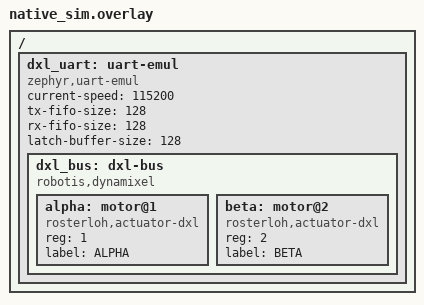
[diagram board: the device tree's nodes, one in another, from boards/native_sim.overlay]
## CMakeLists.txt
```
cmake_minimum_required(VERSION 3.20.0)
find_package(Zephyr REQUIRED HINTS $ENV{ZEPHYR_BASE})
project(actuator_dxl_tests)

set(DXL_TEST_SRC
    ${CMAKE_CURRENT_LIST_DIR}/../../dynamixel/src/fake_servo.c
    ${CMAKE_CURRENT_LIST_DIR}/../../dynamixel/src/fake_bus.c
)

target_sources(app PRIVATE
    src/main.c
    src/test_set_position.c
    src/test_group.c
    ${DXL_TEST_SRC}
)

zephyr_include_directories(../../dynamixel/src)
zephyr_include_directories(${ZEPHYR_DRIVERS_REPO_ROOT}/drivers/dynamixel)
```

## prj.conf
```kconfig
CONFIG_ZTEST=y
CONFIG_LOG=y
CONFIG_SERIAL=y
CONFIG_UART_INTERRUPT_DRIVEN=y
CONFIG_EMUL=y
CONFIG_UART_EMUL=y
CONFIG_ACTUATOR=y
CONFIG_ACTUATOR_DXL=y
CONFIG_DYNAMIXEL=y
CONFIG_FPU=y
# Higher tick resolution so that µs-level timeouts quantise accurately.
CONFIG_SYS_CLOCK_TICKS_PER_SEC=10000
```

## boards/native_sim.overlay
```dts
/*
 * Copyright (c) 2026 Richard Osterloh <richard.osterloh@gmail.com>
 *
 * SPDX-License-Identifier: Apache-2.0
 */

/ {
	dxl_uart: uart-emul {
		compatible = "zephyr,uart-emul";
		current-speed = <115200>;
		tx-fifo-size = <128>;
		rx-fifo-size = <128>;
		latch-buffer-size = <128>;
		status = "okay";

		dxl_bus: dxl-bus {
			compatible = "robotis,dynamixel";
			#address-cells = <1>;
			#size-cells = <0>;
			status = "okay";

			alpha: motor@1 {
				compatible = "rosterloh,actuator-dxl";
				reg = <1>;
				label = "ALPHA";
			};

			beta: motor@2 {
				compatible = "rosterloh,actuator-dxl";
				reg = <2>;
				label = "BETA";
			};
		};
	};
};
```

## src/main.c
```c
/*
 * Copyright (c) 2026 Richard Osterloh <richard.osterloh@gmail.com>
 * SPDX-License-Identifier: Apache-2.0
 */

#include <zephyr/ztest.h>

ZTEST_SUITE(dxl_actuator, NULL, NULL, NULL, NULL, NULL);
```

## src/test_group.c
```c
/*
 * Copyright (c) 2026 Richard Osterloh <richard.osterloh@gmail.com>
 * SPDX-License-Identifier: Apache-2.0
 */

#include <zephyr/ztest.h>
#include <zephyr/device.h>
#include <zephyr/actuator/actuator.h>
#include <zephyr/actuator/actuator_group.h>
#include <drivers/dynamixel.h>

#include "fake_bus.h"

#define DXL_BUS_NODE   DT_NODELABEL(dxl_bus)
#define DXL_UART_NODE  DT_PARENT(DXL_BUS_NODE)
#define DXL_IFACE_NAME DEVICE_DT_NAME(DXL_BUS_NODE)

#define FAKE_BUS_RXWAIT_TO_US 10000U

#define ALPHA DEVICE_DT_GET(DT_NODELABEL(alpha))
#define BETA  DEVICE_DT_GET(DT_NODELABEL(beta))

ACTUATOR_GROUP_DEFINE(arm, ALPHA, BETA);

static const struct device *uart_dev = DEVICE_DT_GET(DXL_UART_NODE);

static struct fake_bus bus;
static int iface;

static void grp_before_each(void *fixture)
{
	ARG_UNUSED(fixture);

	const uint8_t ids[] = {1, 2};
	struct dxl_iface_param p = {
		.rx_timeout = FAKE_BUS_RXWAIT_TO_US,
		.serial = {.baud = 115200, .parity = UART_CFG_PARITY_NONE},
	};

	fake_bus_init(&bus, ids, ARRAY_SIZE(ids));
	fake_bus_attach(&bus, uart_dev);

	iface = dxl_iface_get_by_name(DXL_IFACE_NAME);
	zassert_true(iface >= 0, "iface lookup failed: %d", iface);
	zassert_ok(dxl_init(iface, p), "dxl_init failed");
}

static void grp_after_each(void *fixture)
{
	ARG_UNUSED(fixture);
	dxl_disable(iface);
}

ZTEST_SUITE(dxl_actuator_grp, NULL, NULL, grp_before_each, grp_after_each, NULL);

ZTEST(dxl_actuator_grp, test_group_set_position_succeeds)
{
	struct fake_servo *s0 = fake_bus_get(&bus, 1);
	struct fake_servo *s1 = fake_bus_get(&bus, 2);

	zassert_not_null(s0, "servo 1 not found");
	zassert_not_null(s1, "servo 2 not found");

	zassert_ok(actuator_group_enable(&arm));

	s0->last_tx_len = 0;
	s0->last_instruction = 0;
	s1->last_tx_len = 0;
	s1->last_instruction = 0;

	const float goals[] = {1.0f, -1.0f};
	int err = actuator_group_set_position(&arm, goals);

	zassert_ok(err, "group_set_position rc=%d", err);

	/* SYNC_WRITE is fire-and-forget; yield for TX FIFO drain before asserting. */
	k_sleep(K_MSEC(2));

	/* SYNC_WRITE is broadcast: fake_bus captures the packet in all servos. */
	zassert_true(s0->last_tx_len > 0, "expected SYNC_WRITE bus traffic, got last_tx_len=%u",
		     s0->last_tx_len);
}
```

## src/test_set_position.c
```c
/*
 * Copyright (c) 2026 Richard Osterloh <richard.osterloh@gmail.com>
 * SPDX-License-Identifier: Apache-2.0
 */

#include <zephyr/ztest.h>
#include <zephyr/device.h>
#include <zephyr/actuator/actuator.h>
#include <drivers/dynamixel.h>

#include "fake_bus.h"

#define DXL_BUS_NODE   DT_NODELABEL(dxl_bus)
#define DXL_UART_NODE  DT_PARENT(DXL_BUS_NODE)
#define DXL_IFACE_NAME DEVICE_DT_NAME(DXL_BUS_NODE)

#define FAKE_BUS_RXWAIT_TO_US 10000U

#define ALPHA DEVICE_DT_GET(DT_NODELABEL(alpha))

static const struct device *uart_dev = DEVICE_DT_GET(DXL_UART_NODE);

static struct fake_bus bus;
static int iface;

static void sp_before_each(void *fixture)
{
	ARG_UNUSED(fixture);

	const uint8_t ids[] = {1, 2};
	struct dxl_iface_param p = {
		.rx_timeout = FAKE_BUS_RXWAIT_TO_US,
		.serial = {.baud = 115200, .parity = UART_CFG_PARITY_NONE},
	};

	fake_bus_init(&bus, ids, ARRAY_SIZE(ids));
	fake_bus_attach(&bus, uart_dev);

	iface = dxl_iface_get_by_name(DXL_IFACE_NAME);
	zassert_true(iface >= 0, "iface lookup failed: %d", iface);
	zassert_ok(dxl_init(iface, p), "dxl_init failed");
}

static void sp_after_each(void *fixture)
{
	ARG_UNUSED(fixture);
	dxl_disable(iface);
}

ZTEST_SUITE(dxl_actuator_sp, NULL, NULL, sp_before_each, sp_after_each, NULL);

ZTEST(dxl_actuator_sp, test_set_position_writes_to_bus)
{
	struct fake_servo *s = fake_bus_get(&bus, 1);

	zassert_not_null(s, "servo 1 not found");
	s->last_tx_len = 0;
	s->last_instruction = 0;

	zassert_ok(actuator_enable(ALPHA));
	zassert_ok(actuator_set_position(ALPHA, 1.5707963f)); /* pi/2 */

	/* fake_bus callback drains TX data — verify via captured last_instruction.
	 * set_position issues a WRITE (0x03) instruction for GOAL_POSITION.
	 */
	zassert_true(s->last_tx_len > 0, "expected dynamixel bus traffic, got last_tx_len=%u",
		     s->last_tx_len);
}

ZTEST(dxl_actuator_sp, test_disable_writes_torque_off)
{
	struct fake_servo *s = fake_bus_get(&bus, 1);

	zassert_not_null(s, "servo 1 not found");

	/* Enable first so there's an active state to disable. */
	zassert_ok(actuator_enable(ALPHA));

	s->last_tx_len = 0;
	s->last_instruction = 0;

	zassert_ok(actuator_disable(ALPHA));

	/* disable issues a WRITE for TORQUE_ENABLE=0 */
	zassert_true(s->last_tx_len > 0, "disable should write TORQUE_ENABLE=0 to the bus");
}
```
